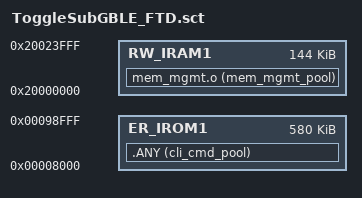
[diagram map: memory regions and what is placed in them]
; *************************************************************
; *** Scatter-Loading Description File generated by uVision ***
; *************************************************************

LR_IROM1 0x000008000 0x00091000  {    ; load region size_region
  ER_IROM1 0x000008000 0x00091000  {  ; load address = execution address
   *.o (RESET, +First)
   *(InRoot$$Sections)
   .ANY (+RO)
  }
  RW_IROM_CLI_CMD_POOL_START+0 {  ; CLI command description pool
	.ANY (cli_cmd_pool)
  }
  RW_IRAM1 0x20000000 0x24000  {  ; RW data & FreeRTOS heap
   .ANY (+RW +ZI)
   .ANY (ram_func)
  }
  RW_IRAM_MEM_MGMT_POOL_START+0 { ; Memory management heap pool
   mem_mgmt.o (mem_mgmt_pool)
  }
}

